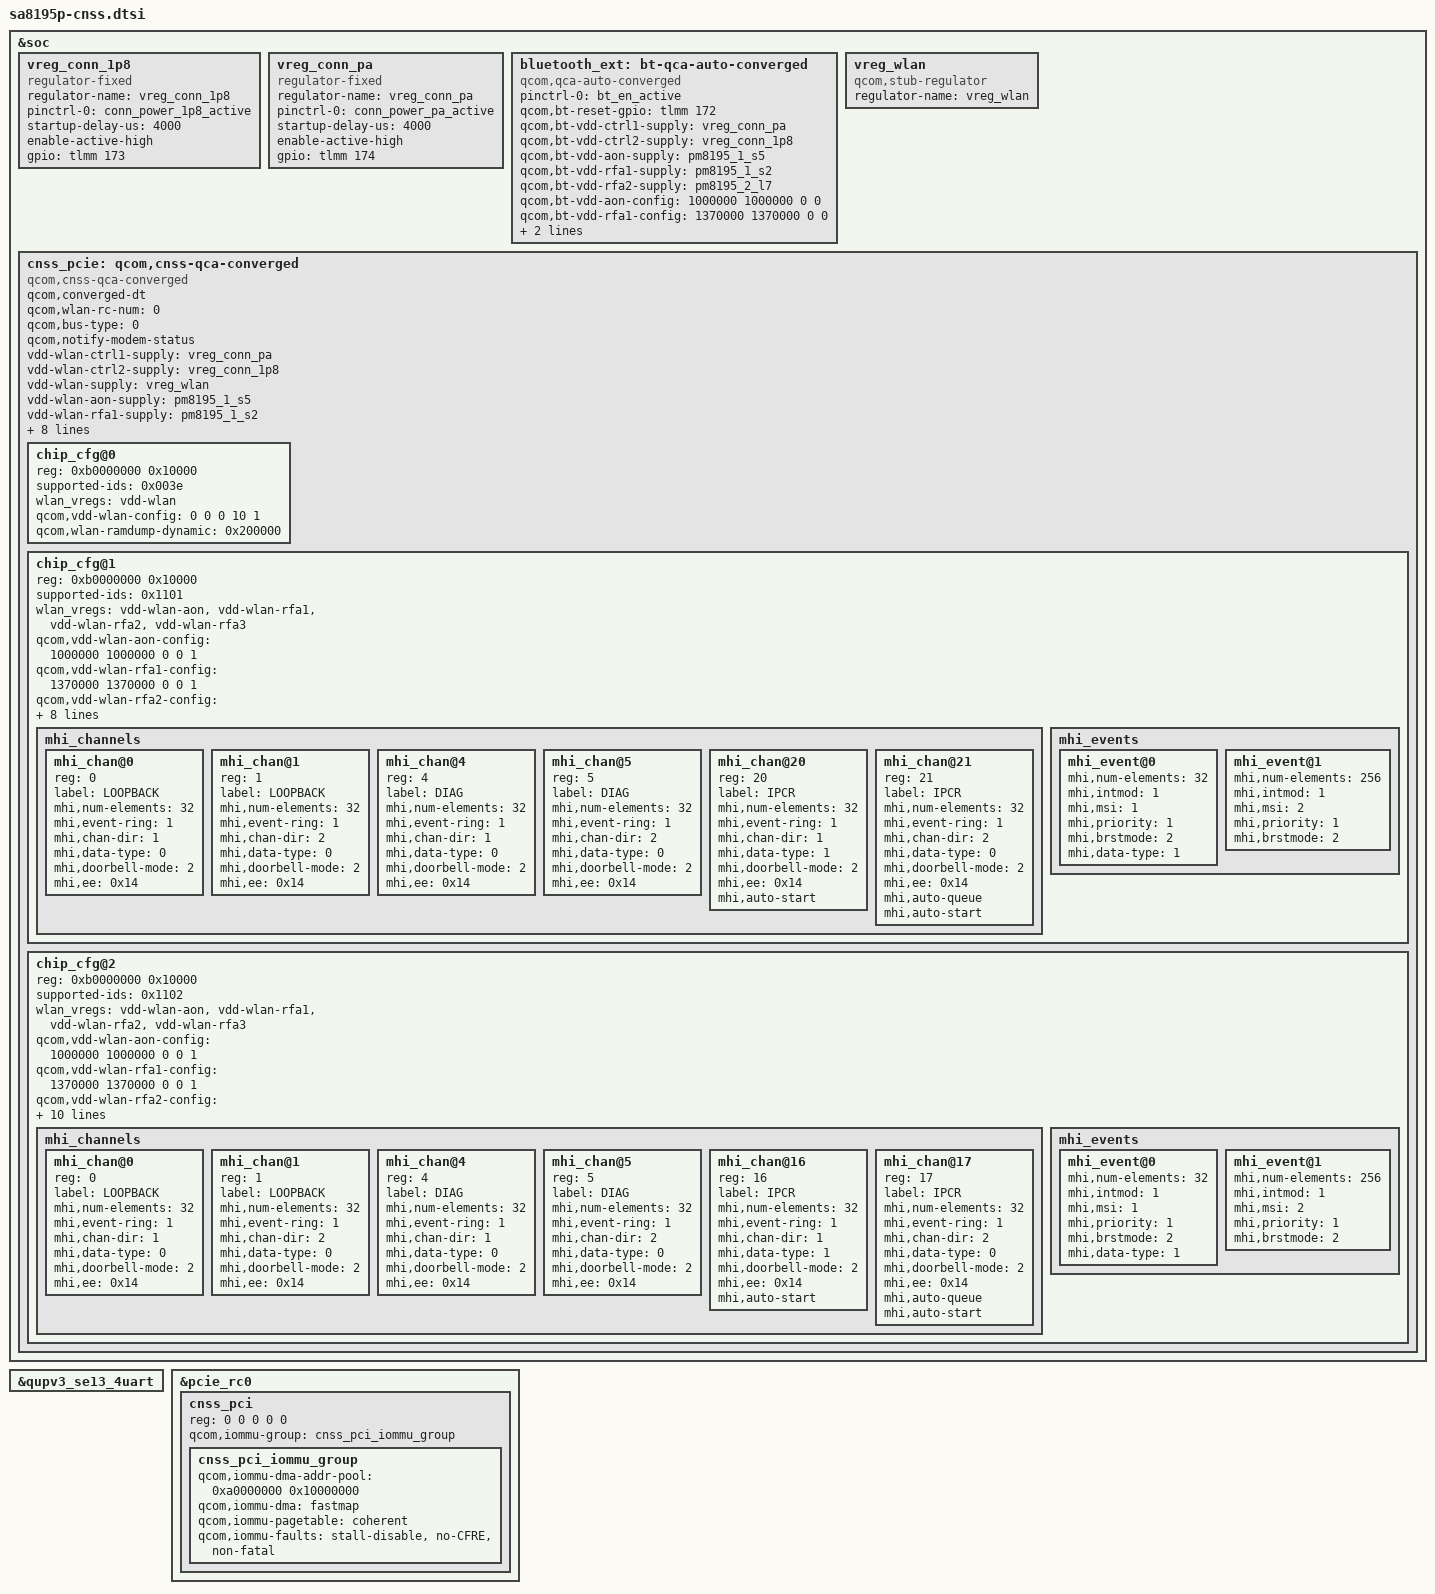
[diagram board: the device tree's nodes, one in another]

&soc {
	/* PWR_CTR2_VDD_1P8 supply */
	vreg_conn_1p8: vreg_conn_1p8 {
		compatible = "regulator-fixed";
		regulator-name = "vreg_conn_1p8";
		pinctrl-names = "default";
		pinctrl-0 = <&conn_power_1p8_active>;
		startup-delay-us = <4000>;
		enable-active-high;
		gpio = <&tlmm 173 0>;
	};

	/* PWR_CTR1_VDD_PA supply */
	vreg_conn_pa: vreg_conn_pa {
		compatible = "regulator-fixed";
		regulator-name = "vreg_conn_pa";
		pinctrl-names = "default";
		pinctrl-0 = <&conn_power_pa_active>;
		startup-delay-us = <4000>;
		enable-active-high;
		gpio = <&tlmm 174 0>;
	};

	bluetooth_ext: bt-qca-auto-converged {
		compatible = "qcom,qca-auto-converged";
		pinctrl-names = "default";
		pinctrl-0 = <&bt_en_active>;
		/* BT_EN */
		qcom,bt-reset-gpio = <&tlmm 172 0>;
		/* PWR_CTR1_VDD_PA */
		qcom,bt-vdd-ctrl1-supply = <&vreg_conn_pa>;
		/* PWR_CTR2_VDD_1P8 */
		qcom,bt-vdd-ctrl2-supply = <&vreg_conn_1p8>;
		qcom,bt-vdd-aon-supply = <&pm8195_1_s5>;
		qcom,bt-vdd-rfa1-supply = <&pm8195_1_s2>;
		qcom,bt-vdd-rfa2-supply = <&pm8195_2_l7>;

		/* <vol_min, vol_max, load_curr, is_retention_supp> */
		qcom,bt-vdd-aon-config = <1000000 1000000 0 0>;
		qcom,bt-vdd-rfa1-config = <1370000 1370000 0 0>;
		qcom,bt-vdd-rfa2-config = <1900000 1900000 450000 0>;
	};

	/* Rome 3.3V supply */
	vreg_wlan: vreg_wlan {
		compatible = "qcom,stub-regulator";
		regulator-name = "vreg_wlan";
	};

	cnss_pcie: qcom,cnss-qca-converged {
		compatible = "qcom,cnss-qca-converged";

		qcom,converged-dt;
		qcom,wlan-rc-num = <0>;
		qcom,bus-type=<0>;
		qcom,notify-modem-status;

		#address-cells=<1>;
		#size-cells=<1>;
		ranges = <0xb0000000 0xb0000000 0x10000>;

		vdd-wlan-ctrl1-supply = <&vreg_conn_pa>;
		vdd-wlan-ctrl2-supply = <&vreg_conn_1p8>;
		vdd-wlan-supply = <&vreg_wlan>;
		vdd-wlan-aon-supply = <&pm8195_1_s5>;
		vdd-wlan-rfa1-supply = <&pm8195_1_s2>;
		vdd-wlan-rfa2-supply = <&pm8195_2_s5>;
		vdd-wlan-rfa3-supply = <&pm8195_2_l7>;

		wlan_vregs = "vdd-wlan-ctrl1", "vdd-wlan-ctrl2";
		qcom,vdd-wlan-ctrl1-config = <0 0 0 0 0>;
		qcom,vdd-wlan-ctrl2-config = <0 0 0 0 0>;
		wlan-en-gpio = <&tlmm 169 0>;
		pinctrl-names = "wlan_en_active", "wlan_en_sleep";
		pinctrl-0 = <&cnss_wlan_en_active>;
		pinctrl-1 = <&cnss_wlan_en_sleep>;

		chip_cfg@0 {
			reg = <0xb0000000 0x10000>;
			reg-names = "smmu_iova_ipa";

			supported-ids = <0x003e>;
			wlan_vregs = "vdd-wlan";
			qcom,vdd-wlan-config = <0 0 0 10 1>;

			qcom,wlan-ramdump-dynamic = <0x200000>;
		};

		chip_cfg@1 {
			reg = <0xb0000000 0x10000>;
			reg-names = "smmu_iova_ipa";

			supported-ids = <0x1101>;
			wlan_vregs = "vdd-wlan-aon", "vdd-wlan-rfa1",
				   "vdd-wlan-rfa2", "vdd-wlan-rfa3";
			qcom,vdd-wlan-aon-config = <1000000 1000000 0 0 1>;
			qcom,vdd-wlan-rfa1-config = <1370000 1370000 0 0 1>;
			qcom,vdd-wlan-rfa2-config = <2040000 2040000 0 0 1>;
			qcom,vdd-wlan-rfa3-config = <1900000 1900000 450000 0 1>;
			qcom,wlan-ramdump-dynamic = <0x400000>;
			mhi,max-channels = <30>;
			mhi,timeout = <10000>;
			mhi,buffer-len = <0x8000>;
			mhi,m2-no-db-access;

			mhi_channels {
				#address-cells = <1>;
				#size-cells = <0>;
				mhi_chan@0 {
					reg = <0>;
					label = "LOOPBACK";
					mhi,num-elements = <32>;
					mhi,event-ring = <1>;
					mhi,chan-dir = <1>;
					mhi,data-type = <0>;
					mhi,doorbell-mode = <2>;
					mhi,ee = <0x14>;
				};

				mhi_chan@1 {
					reg = <1>;
					label = "LOOPBACK";
					mhi,num-elements = <32>;
					mhi,event-ring = <1>;
					mhi,chan-dir = <2>;
					mhi,data-type = <0>;
					mhi,doorbell-mode = <2>;
					mhi,ee = <0x14>;
				};

				mhi_chan@4 {
					reg = <4>;
					label = "DIAG";
					mhi,num-elements = <32>;
					mhi,event-ring = <1>;
					mhi,chan-dir = <1>;
					mhi,data-type = <0>;
					mhi,doorbell-mode = <2>;
					mhi,ee = <0x14>;
				};

				mhi_chan@5 {
					reg = <5>;
					label = "DIAG";
					mhi,num-elements = <32>;
					mhi,event-ring = <1>;
					mhi,chan-dir = <2>;
					mhi,data-type = <0>;
					mhi,doorbell-mode = <2>;
					mhi,ee = <0x14>;
				};

				mhi_chan@20 {
					reg = <20>;
					label = "IPCR";
					mhi,num-elements = <32>;
					mhi,event-ring = <1>;
					mhi,chan-dir = <1>;
					mhi,data-type = <1>;
					mhi,doorbell-mode = <2>;
					mhi,ee = <0x14>;
					mhi,auto-start;
				};

				mhi_chan@21 {
					reg = <21>;
					label = "IPCR";
					mhi,num-elements = <32>;
					mhi,event-ring = <1>;
					mhi,chan-dir = <2>;
					mhi,data-type = <0>;
					mhi,doorbell-mode = <2>;
					mhi,ee = <0x14>;
					mhi,auto-queue;
					mhi,auto-start;
				};
			};

			mhi_events {
				mhi_event@0 {
					mhi,num-elements = <32>;
					mhi,intmod = <1>;
					mhi,msi = <1>;
					mhi,priority = <1>;
					mhi,brstmode = <2>;
					mhi,data-type = <1>;
				};

				mhi_event@1 {
					mhi,num-elements = <256>;
					mhi,intmod = <1>;
					mhi,msi = <2>;
					mhi,priority = <1>;
					mhi,brstmode = <2>;
				};
			};
		};

		chip_cfg@2 {
			reg = <0xb0000000 0x10000>;
			reg-names = "smmu_iova_ipa";

			supported-ids = <0x1102>;
			wlan_vregs = "vdd-wlan-aon", "vdd-wlan-rfa1",
				   "vdd-wlan-rfa2", "vdd-wlan-rfa3";
			qcom,vdd-wlan-aon-config = <1000000 1000000 0 0 1>;
			qcom,vdd-wlan-rfa1-config = <1370000 1370000 0 0 1>;
			qcom,vdd-wlan-rfa2-config = <2040000 2040000 0 0 1>;
			qcom,vdd-wlan-rfa3-config = <1900000 1900000 450000 0 1>;

			qcom,wlan-ramdump-dynamic = <0x400000>;
			mhi,max-channels = <30>;
			mhi,timeout = <10000>;
			mhi,ee = <0x3>, <0x4>;
			mhi,ee-names = "SBL", "RDDM";
			mhi,bhie-offset = <0x0324>;
			mhi,m2-no-db-access;

			mhi_channels {
				#address-cells = <1>;
				#size-cells = <0>;
				mhi_chan@0 {
					reg = <0>;
					label = "LOOPBACK";
					mhi,num-elements = <32>;
					mhi,event-ring = <1>;
					mhi,chan-dir = <1>;
					mhi,data-type = <0>;
					mhi,doorbell-mode = <2>;
					mhi,ee = <0x14>;
				};

				mhi_chan@1 {
					reg = <1>;
					label = "LOOPBACK";
					mhi,num-elements = <32>;
					mhi,event-ring = <1>;
					mhi,chan-dir = <2>;
					mhi,data-type = <0>;
					mhi,doorbell-mode = <2>;
					mhi,ee = <0x14>;
				};

				mhi_chan@4 {
					reg = <4>;
					label = "DIAG";
					mhi,num-elements = <32>;
					mhi,event-ring = <1>;
					mhi,chan-dir = <1>;
					mhi,data-type = <0>;
					mhi,doorbell-mode = <2>;
					mhi,ee = <0x14>;
				};

				mhi_chan@5 {
					reg = <5>;
					label = "DIAG";
					mhi,num-elements = <32>;
					mhi,event-ring = <1>;
					mhi,chan-dir = <2>;
					mhi,data-type = <0>;
					mhi,doorbell-mode = <2>;
					mhi,ee = <0x14>;
				};

				mhi_chan@16 {
					reg = <16>;
					label = "IPCR";
					mhi,num-elements = <32>;
					mhi,event-ring = <1>;
					mhi,chan-dir = <1>;
					mhi,data-type = <1>;
					mhi,doorbell-mode = <2>;
					mhi,ee = <0x14>;
					mhi,auto-start;
				};

				mhi_chan@17 {
					reg = <17>;
					label = "IPCR";
					mhi,num-elements = <32>;
					mhi,event-ring = <1>;
					mhi,chan-dir = <2>;
					mhi,data-type = <0>;
					mhi,doorbell-mode = <2>;
					mhi,ee = <0x14>;
					mhi,auto-queue;
					mhi,auto-start;
				};
			};

			mhi_events {
				mhi_event@0 {
					mhi,num-elements = <32>;
					mhi,intmod = <1>;
					mhi,msi = <1>;
					mhi,priority = <1>;
					mhi,brstmode = <2>;
					mhi,data-type = <1>;
				};

				mhi_event@1 {
					mhi,num-elements = <256>;
					mhi,intmod = <1>;
					mhi,msi = <2>;
					mhi,priority = <1>;
					mhi,brstmode = <2>;
				};
			};
		};
	};
};

&qupv3_se13_4uart {
	status = "ok";
};

&pcie_rc0 {
	cnss_pci: cnss_pci {
		reg = <0 0 0 0 0>;
		qcom,iommu-group = <&cnss_pci_iommu_group>;

		#address-cells = <1>;
		#size-cells = <1>;

		cnss_pci_iommu_group: cnss_pci_iommu_group {
		qcom,iommu-dma-addr-pool = <0xa0000000 0x10000000>;
		qcom,iommu-dma = "fastmap";
		qcom,iommu-pagetable = "coherent";
		qcom,iommu-faults = "stall-disable", "no-CFRE",
			 "non-fatal";
		};
	};
};
